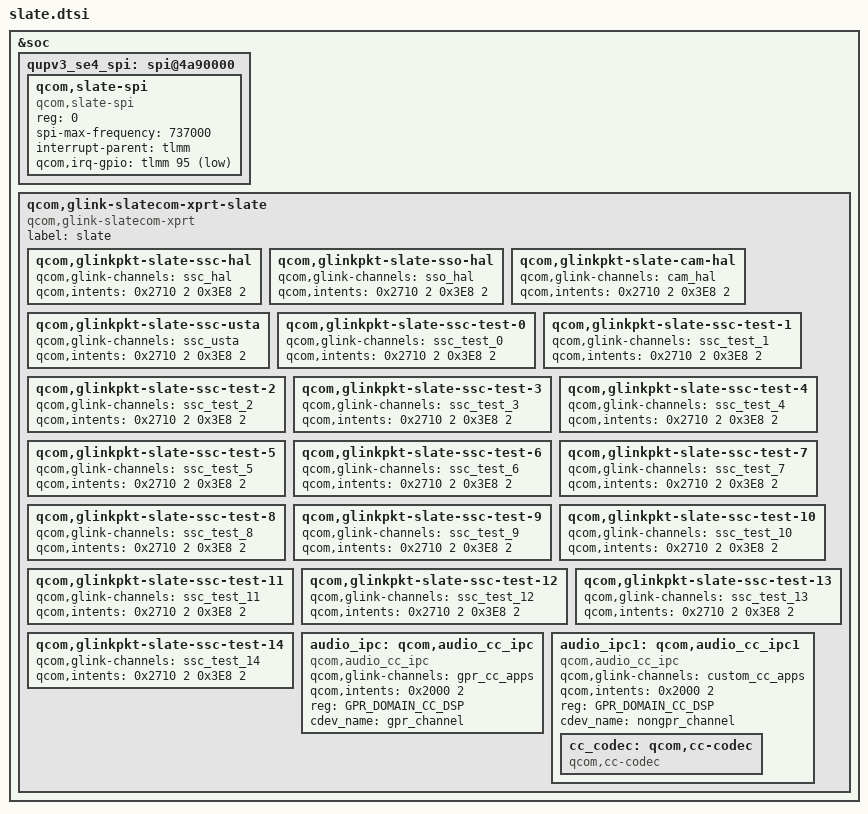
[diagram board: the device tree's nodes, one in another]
#include "dt-bindings/sound/qcom,gpr.h"

&soc {
	qupv3_se4_spi: spi@4a90000 {  /* BLSP4 QUP3*/
		status = "ok";
		qcom,slate-spi {
			compatible = "qcom,slate-spi";
			reg = <0>;
			spi-max-frequency = <737000>;
			interrupt-parent = <&tlmm>;
			qcom,irq-gpio = <&tlmm 95 1>;
		};
	};

	qcom,glink-slatecom-xprt-slate {
		compatible = "qcom,glink-slatecom-xprt";
		label = "slate";

		qcom,glinkpkt-slate-ssc-hal {
			qcom,glink-channels = "ssc_hal";
			qcom,intents = <0x2710 2
					0x3E8  2>;
		};

		qcom,glinkpkt-slate-sso-hal {
			qcom,glink-channels = "sso_hal";
			qcom,intents = <0x2710 2
					0x3E8  2>;
		};

		qcom,glinkpkt-slate-cam-hal {
			qcom,glink-channels = "cam_hal";
			qcom,intents = <0x2710 2
					0x3E8  2>;
		};

		qcom,glinkpkt-slate-ssc-usta {
			qcom,glink-channels = "ssc_usta";
			qcom,intents = <0x2710 2
					0x3E8  2>;
		};

		qcom,glinkpkt-slate-ssc-test-0 {
			qcom,glink-channels = "ssc_test_0";
			qcom,intents = <0x2710 2
					0x3E8  2>;
		};

		qcom,glinkpkt-slate-ssc-test-1 {
			qcom,glink-channels = "ssc_test_1";
			qcom,intents = <0x2710 2
					0x3E8  2>;
		};

		qcom,glinkpkt-slate-ssc-test-2 {
			qcom,glink-channels = "ssc_test_2";
			qcom,intents = <0x2710 2
					0x3E8  2>;
		};

		qcom,glinkpkt-slate-ssc-test-3 {
			qcom,glink-channels = "ssc_test_3";
			qcom,intents = <0x2710 2
					0x3E8  2>;
		};

		qcom,glinkpkt-slate-ssc-test-4 {
			qcom,glink-channels = "ssc_test_4";
			qcom,intents = <0x2710 2
					0x3E8  2>;
		};

		qcom,glinkpkt-slate-ssc-test-5 {
			qcom,glink-channels = "ssc_test_5";
			qcom,intents = <0x2710 2
					0x3E8  2>;
		};

		qcom,glinkpkt-slate-ssc-test-6 {
			qcom,glink-channels = "ssc_test_6";
			qcom,intents = <0x2710 2
					0x3E8  2>;
		};

		qcom,glinkpkt-slate-ssc-test-7 {
			qcom,glink-channels = "ssc_test_7";
			qcom,intents = <0x2710 2
					0x3E8  2>;
		};

		qcom,glinkpkt-slate-ssc-test-8 {
			qcom,glink-channels = "ssc_test_8";
			qcom,intents = <0x2710 2
					0x3E8  2>;
		};

		qcom,glinkpkt-slate-ssc-test-9 {
			qcom,glink-channels = "ssc_test_9";
			qcom,intents = <0x2710 2
					0x3E8  2>;
		};

		qcom,glinkpkt-slate-ssc-test-10 {
			qcom,glink-channels = "ssc_test_10";
			qcom,intents = <0x2710 2
					0x3E8  2>;
		};

		qcom,glinkpkt-slate-ssc-test-11 {
			qcom,glink-channels = "ssc_test_11";
			qcom,intents = <0x2710 2
					0x3E8  2>;
		};

		qcom,glinkpkt-slate-ssc-test-12 {
			qcom,glink-channels = "ssc_test_12";
			qcom,intents = <0x2710 2
					0x3E8  2>;
		};

		qcom,glinkpkt-slate-ssc-test-13 {
			qcom,glink-channels = "ssc_test_13";
			qcom,intents = <0x2710 2
					0x3E8  2>;
		};

		qcom,glinkpkt-slate-ssc-test-14 {
			qcom,glink-channels = "ssc_test_14";
			qcom,intents = <0x2710 2
					0x3E8  2>;
		};

		audio_ipc: qcom,audio_cc_ipc {
			compatible = "qcom,audio_cc_ipc";
			qcom,glink-channels = "gpr_cc_apps";
			qcom,intents = <0x2000 2>;
			reg = <GPR_DOMAIN_CC_DSP>;
			cdev_name = "gpr_channel";
		};

		audio_ipc1: qcom,audio_cc_ipc1 {
			compatible = "qcom,audio_cc_ipc";
			qcom,glink-channels = "custom_cc_apps";
			qcom,intents = <0x2000 2>;
			reg = <GPR_DOMAIN_CC_DSP>;
			cdev_name = "nongpr_channel";

			cc_codec: qcom,cc-codec {
				compatible = "qcom,cc-codec";
			};
		};
	};
};
